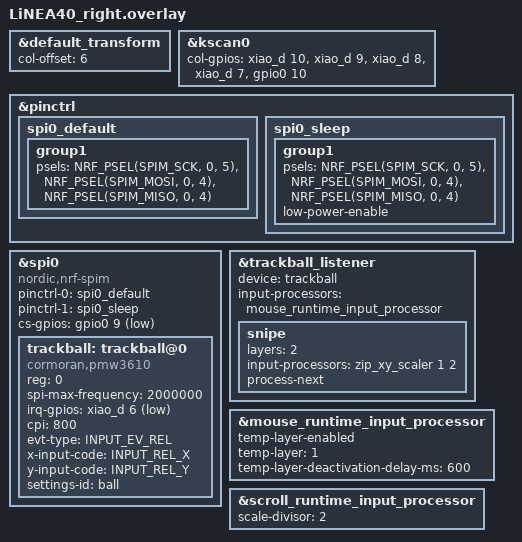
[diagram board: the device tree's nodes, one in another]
#include "LiNEA40.dtsi"
&default_transform {
    col-offset = <6>;
};

&kscan0 {
    col-gpios
        = <&xiao_d 10 GPIO_ACTIVE_HIGH> //col0-D10
        , <&xiao_d 9 GPIO_ACTIVE_HIGH>  //col1-D9
        , <&xiao_d 8 GPIO_ACTIVE_HIGH>  //col2-D8
        , <&xiao_d 7 GPIO_ACTIVE_HIGH>  //col3-D7
        , <&gpio0 10 GPIO_ACTIVE_HIGH>  //col4-NFC2
        ;
};


&pinctrl {
    spi0_default: spi0_default {
        group1 {
            psels = <NRF_PSEL(SPIM_SCK, 0, 5)>   // SCLK-D5
                  , <NRF_PSEL(SPIM_MOSI, 0, 4)>  // SDIO-D4
                  , <NRF_PSEL(SPIM_MISO, 0, 4)>  // SDIO-D4
                  ;
        };
    };

    spi0_sleep: spi0_sleep {
        group1 {
            psels = <NRF_PSEL(SPIM_SCK, 0, 5)>   // SCLK-D5
                  , <NRF_PSEL(SPIM_MOSI, 0, 4)>  // SDIO-D4
                  , <NRF_PSEL(SPIM_MISO, 0, 4)>  // SDIO-D4
                  ;
            low-power-enable;
        };
    };
};

&spi0 {
    status = "okay";
    compatible = "nordic,nrf-spim";
    pinctrl-0 = <&spi0_default>;
    pinctrl-1 = <&spi0_sleep>;
    pinctrl-names = "default", "sleep";
    cs-gpios = <&gpio0 9 GPIO_ACTIVE_LOW>; //NCS-NFC1

    trackball: trackball@0 {
        status = "okay";
        compatible = "cormoran,pmw3610";
        reg = <0>;
        spi-max-frequency = <2000000>;
        irq-gpios = <&xiao_d 6 (GPIO_ACTIVE_LOW | GPIO_PULL_UP)>; //MOT-D6
        cpi = <800>;
        evt-type = <INPUT_EV_REL>;
        x-input-code = <INPUT_REL_X>;
        y-input-code = <INPUT_REL_Y>;
        settings-id = "ball";   // 8文字以内
        // 旧ドライバーの automouse-layer / snipe-layers / scroll-layers は
        // 新ドライバーには無いため、下の input-processor で置き換える。
    };
};

&trackball_listener {
    status = "okay";
    device = <&trackball>;
    // DYA Studio のトラックボール設定（速度・回転・反転・オートマウス）
    input-processors = <&mouse_runtime_input_processor>;

    // スナイプ（旧 snipe-layers = <2>, CPI 800 -> 400 相当）
    snipe {
        layers = <2>;
        input-processors = <&zip_xy_scaler 1 2>;
        process-next;   // 続けて mouse_runtime_input_processor も適用
    };
};

// オートマウス（旧 automouse-layer = <1>, AUTOMOUSE_TIMEOUT_MS=600 相当）
// DYA Studio から実行時に変更可能。
&mouse_runtime_input_processor {
    temp-layer-enabled;
    temp-layer = <1>;
    temp-layer-deactivation-delay-ms = <600>;
};

// スクロール（keymap の scroller から参照。旧 SCROLL_TICK=2 相当）
&scroll_runtime_input_processor {
    scale-divisor = <2>;
};
